# MB9AFA3xN register map
File version: 1.7
CPU: 
Registers are 8-bit, read-write, reset 0x0 unless marked. A register's access mark holds for its fields unless they carry their own. Offsets are from the block's base; [hi:lo] are bit positions.

## INTREQ — Interrupts
Base 0x40031000
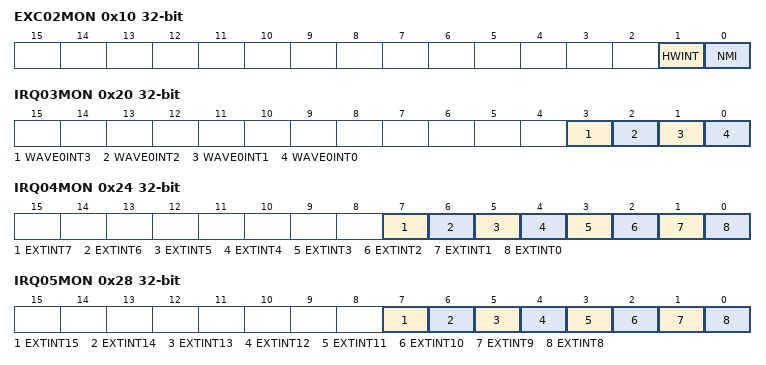
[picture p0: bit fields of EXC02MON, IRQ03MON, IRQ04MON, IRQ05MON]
0x10 EXC02MON 32-bit ro — EXC02 batch read register
  [1] HWINT — Hardware watchdog timer interrupt request
  [0] NMI — External NMIX pin interrupt request
0x14 IRQ00MON 32-bit ro — IRQ00 Batch Read Register
  [0] FCSINT — Anomalous frequency detection by CSV interrupt request
0x18 IRQ01MON 32-bit ro — IRQ01 Batch Read Register
  [0] SWWDTINT — Software watchdog timer interrupt request
0x1C IRQ02MON 32-bit ro — IRQ02 Batch Read Register
  [0] LVDINT — Low voltage detection (LVD) interrupt request
0x20 IRQ03MON 32-bit ro — IRQ03 Batch Read Register
  [3] WAVE0INT3 — WFG timer 54 interrupt request in MFT unit 0
  [2] WAVE0INT2 — WFG timer 32 interrupt request in MFT unit 0
  [1] WAVE0INT1 — WFG timer 10 interrupt request in MFT unit 0
  [0] WAVE0INT0 — DTIF (motor emergency stop) interrupt request in MFT unit 0
0x24 IRQ04MON 32-bit ro — IRQ04 Batch Read Register
  [7] EXTINT7 — Interrupt request on external interrupt ch.7
  [6] EXTINT6 — Interrupt request on external interrupt ch.6
  [5] EXTINT5 — Interrupt request on external interrupt ch.5
  [4] EXTINT4 — Interrupt request on external interrupt ch.4
  [3] EXTINT3 — Interrupt request on external interrupt ch.3
  [2] EXTINT2 — Interrupt request on external interrupt ch.2
  [1] EXTINT1 — Interrupt request on external interrupt ch.1
  [0] EXTINT0 — Interrupt request on external interrupt ch.0
0x28 IRQ05MON 32-bit ro — IRQ05 Batch Read Register
  [7] EXTINT15 — Interrupt request on external interrupt ch.15
  [6] EXTINT14 — Interrupt request on external interrupt ch.14
  [5] EXTINT13 — Interrupt request on external interrupt ch.13
  [4] EXTINT12 — Interrupt request on external interrupt ch.12
  [3] EXTINT11 — Interrupt request on external interrupt ch.11
  [2] EXTINT10 — Interrupt request on external interrupt ch.10
  [1] EXTINT9 — Interrupt request on external interrupt ch.9
  [0] EXTINT8 — Interrupt request on external interrupt ch.8
0x2C IRQ06MON 32-bit ro — IRQ06 Batch Read Register
  [0] MFSINT — Reception interrupt request on MFS ch.0
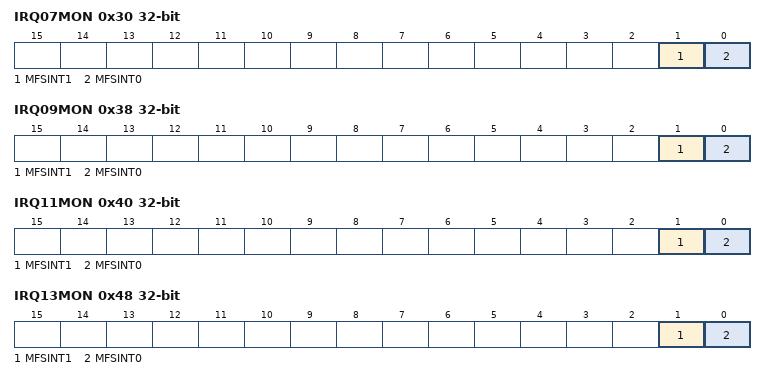
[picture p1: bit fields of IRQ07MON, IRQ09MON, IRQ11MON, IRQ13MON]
0x30 IRQ07MON 32-bit ro — IRQ07 Batch Read Register
  [1] MFSINT1 — Status interrupt request on MFS ch.0
  [0] MFSINT0 — Transmission interrupt request on MFS ch.0
0x34 IRQ08MON 32-bit ro — IRQ08 Batch Read Register
  [0] MFSINT — Reception interrupt request on MFS ch.1
0x38 IRQ09MON 32-bit ro — IRQ9 Batch Read Register
  [1] MFSINT1 — Status interrupt request on MFS ch.1
  [0] MFSINT0 — Transmission interrupt request on MFS ch.1
0x3C IRQ10MON 32-bit ro — IRQ10 Batch Read Register
  [0] MFSINT — Reception interrupt request on MFS ch.2
0x40 IRQ11MON 32-bit ro — IRQ11 Batch Read Register
  [1] MFSINT1 — Status interrupt request on MFS ch.2
  [0] MFSINT0 — Transmission interrupt request on MFS ch.2
0x44 IRQ12MON 32-bit ro — IRQ12 Batch Read Register
  [0] MFSINT — Reception interrupt request on MFS ch.3
0x48 IRQ13MON 32-bit ro — IRQ13 Batch Read Register
  [1] MFSINT1 — Status interrupt request on MFS ch.3
  [0] MFSINT0 — Transmission interrupt request on MFS ch.3
0x4C IRQ14MON 32-bit ro — IRQ14 Batch Read Register
  [0] MFSINT — Reception interrupt request on MFS ch.4
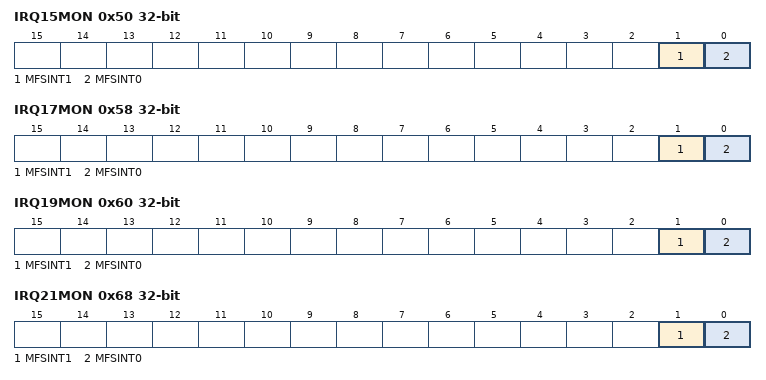
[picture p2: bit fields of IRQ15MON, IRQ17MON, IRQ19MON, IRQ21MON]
0x50 IRQ15MON 32-bit ro — IRQ15 Batch Read Register
  [1] MFSINT1 — Status interrupt request on MFS ch.4
  [0] MFSINT0 — Transmission interrupt request on MFS ch.4
0x54 IRQ16MON 32-bit ro — IRQ16 Batch Read Register
  [0] MFSINT — Reception interrupt request on MFS ch.5
0x58 IRQ17MON 32-bit ro — IRQ17 Batch Read Register
  [1] MFSINT1 — Status interrupt request on MFS ch.5
  [0] MFSINT0 — Transmission interrupt request on MFS ch.5
0x5C IRQ18MON 32-bit ro — IRQ18 Batch Read Register
  [0] MFSINT — Reception interrupt request on MFS ch.6
0x60 IRQ19MON 32-bit ro — IRQ19 Batch Read Register
  [1] MFSINT1 — Status interrupt request on MFS ch.6
  [0] MFSINT0 — Transmission interrupt request on MFS ch.6
0x64 IRQ20MON 32-bit ro — IRQ20 Batch Read Register
  [0] MFSINT — Reception interrupt request on MFS ch.7
0x68 IRQ21MON 32-bit ro — IRQ21 Batch Read Register
  [1] MFSINT1 — Status interrupt request on MFS ch.7
  [0] MFSINT0 — Transmission interrupt request on MFS ch.7
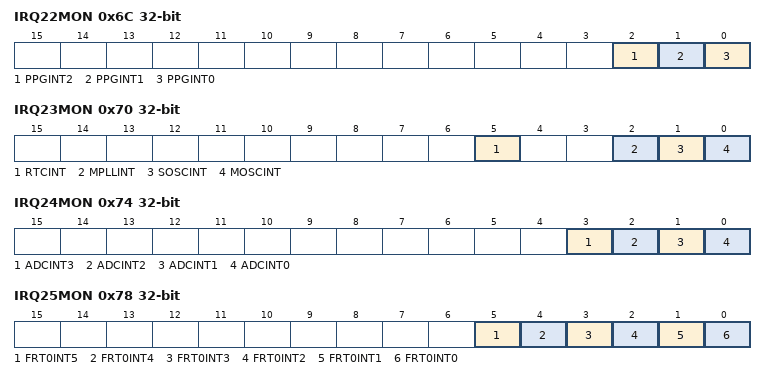
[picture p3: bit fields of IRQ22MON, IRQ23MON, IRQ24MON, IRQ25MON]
0x6C IRQ22MON 32-bit ro — IRQ22 Batch Read Register
  [2] PPGINT2 — Interrupt request on PPG ch.4
  [1] PPGINT1 — Interrupt request on PPG ch.2
  [0] PPGINT0 — Interrupt request on PPG ch.0
0x70 IRQ23MON 32-bit ro — IRQ23 Batch Read Register
  [5] RTCINT — RTC interrupt request
  [2] MPLLINT — Stabilization wait completion interrupt request for main PLL oscillation
  [1] SOSCINT — Stabilization wait completion interrupt request for sub-clock oscillation
  [0] MOSCINT — Stabilization wait completion interrupt request for main clock oscillation
0x74 IRQ24MON 32-bit ro — IRQ24 Batch Read Register
  [3] ADCINT3 — Conversion result comparison interrupt request in the corresponding A/D unit 0.
  [2] ADCINT2 — FIFO overrun interrupt request in the corresponding A/D unit 0.
  [1] ADCINT1 — Scan conversion interrupt request in the corresponding A/D unit 0.
  [0] ADCINT0 — Priority conversion interrupt request in the corresponding A/D unit 0.
0x78 IRQ25MON 32-bit ro — IRQ25 Batch Read Register
  [5] FRT0INT5 — Zero detection interrupt request on the free run timer ch.2 in the MFT unit 0
  [4] FRT0INT4 — Zero detection interrupt request on the free run timer ch.1 in the MFT unit 0
  [3] FRT0INT3 — Zero detection interrupt request on the free run timer ch.0 in the MFT unit 0
  [2] FRT0INT2 — Peak value detection interrupt request on the free run timer ch.2 in the MFT unit 0
  [1] FRT0INT1 — Peak value detection interrupt request on the free run timer ch.1 in the MFT unit 0
  [0] FRT0INT0 — Peak value detection interrupt request on the free run timer ch.0 in the MFT unit 0
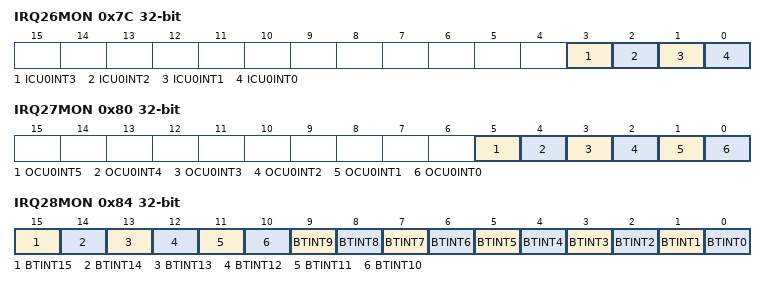
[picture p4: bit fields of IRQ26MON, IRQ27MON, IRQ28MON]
0x7C IRQ26MON 32-bit ro — IRQ26 Batch Read Register
  [3] ICU0INT3 — Interrupt request on the input capture ch.3 in the MFT unit 0
  [2] ICU0INT2 — Interrupt request on the input capture ch.2 in the MFT unit 0
  [1] ICU0INT1 — Interrupt request on the input capture ch.1 in the MFT unit 0
  [0] ICU0INT0 — Interrupt request on the input capture ch.0 in the MFT unit 0
0x80 IRQ27MON 32-bit ro — IRQ27 Batch Read Register
  [5] OCU0INT5 — Interrupt request on the output compare ch.5 in the MFT unit 0
  [4] OCU0INT4 — Interrupt request on the output compare ch.4 in the MFT unit 0
  [3] OCU0INT3 — Interrupt request on the output compare ch.3 in the MFT unit 0
  [2] OCU0INT2 — Interrupt request on the output compare ch.2 in the MFT unit 0
  [1] OCU0INT1 — Interrupt request on the output compare ch.1 in the MFT unit 0
  [0] OCU0INT0 — Interrupt request on the output compare ch.0 in the MFT unit 0
0x84 IRQ28MON 32-bit — IRQ28 Batch Read Register
  [15] BTINT15 ro — IRQ1 interrupt request on the base timer ch.7
  [14] BTINT14 ro — IRQ0 interrupt request on the base timer ch.7
  [13] BTINT13 ro — IRQ1 interrupt request on the base timer ch.6
  [12] BTINT12 ro — IRQ0 interrupt request on the base timer ch.6
  [11] BTINT11 ro — IRQ1 interrupt request on the base timer ch.5
  [10] BTINT10 ro — IRQ0 interrupt request on the base timer ch.5
  [9] BTINT9 ro — IRQ1 interrupt request on the base timer ch.4
  [8] BTINT8 ro — IRQ0 interrupt request on the base timer ch.4
  [7] BTINT7 ro — IRQ1 interrupt request on the base timer ch.3
  [6] BTINT6 ro — IRQ0 interrupt request on the base timer ch.3
  [5] BTINT5 ro — IRQ1 interrupt request on the base timer ch.2
  [4] BTINT4 ro — IRQ0 interrupt request on the base timer ch.2
  [3] BTINT3 ro — IRQ1 interrupt request on the base timer ch.1
  [2] BTINT2 ro — IRQ0 interrupt request on the base timer ch.1
  [1] BTINT1 ro — IRQ1 interrupt request on the base timer ch.0
  [0] BTINT0 ro — IRQ0 interrupt request on the base timer ch.0
0x88 IRQ29MON 32-bit — IRQ29 Batch Read Register
  [4] LCDCINT ro — LCDC interrupt request for LCD controller
0x8C IRQ30MON 32-bit — IRQ30 Batch Read Register
  [5] RCEC0INT ro — Interrupt request for HDMI-CEC/Remote Control Reception ch.0
0x90 IRQ31MON 32-bit — IRQ31 Batch Read Register
  [6] RCEC1INT ro — Interrupt request for HDMI-CEC/Remote Control Reception ch.1
